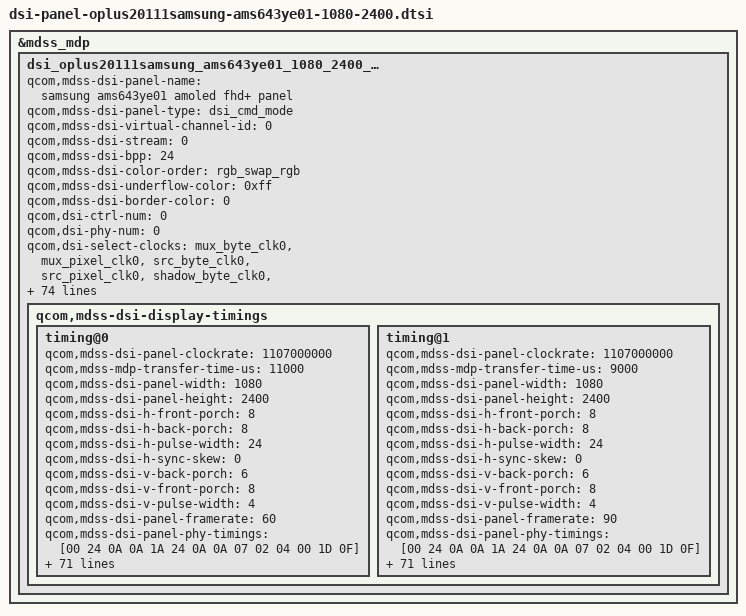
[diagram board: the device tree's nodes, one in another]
// SPDX-License-Identifier: GPL-2.0-only
/*
* Copyright (C) 2018-2020 Oplus. All rights reserved.
*/

&mdss_mdp {
	dsi_oplus20111samsung_ams643ye01_1080_2400_cmd: qcom,mdss_dsi_oplus20111samsung_ams643ye01_1080_2400_cmd {
		qcom,mdss-dsi-panel-name =
		  "samsung ams643ye01 amoled fhd+ panel";
		qcom,mdss-dsi-panel-type = "dsi_cmd_mode";
		qcom,mdss-dsi-virtual-channel-id = <0>;
		qcom,mdss-dsi-stream = <0>;
		qcom,mdss-dsi-bpp = <24>;
		qcom,mdss-dsi-color-order = "rgb_swap_rgb";
		qcom,mdss-dsi-underflow-color = <0xff>;
		qcom,mdss-dsi-border-color = <0>;

		qcom,dsi-ctrl-num = <0>;
		qcom,dsi-phy-num = <0>;
		qcom,dsi-select-clocks = "src_byte_clk0", "src_pixel_clk0";

		qcom,mdss-dsi-traffic-mode = "non_burst_sync_event";
		qcom,mdss-dsi-lane-map = "lane_map_0123";
		qcom,mdss-dsi-bllp-eof-power-mode;
		qcom,mdss-dsi-bllp-power-mode;
		qcom,mdss-dsi-lane-0-state;
		qcom,mdss-dsi-lane-1-state;
		qcom,mdss-dsi-lane-2-state;
		qcom,mdss-dsi-lane-3-state;
		qcom,mdss-dsi-dma-trigger = "trigger_sw";
		qcom,mdss-dsi-mdp-trigger = "none";
		qcom,mdss-dsi-reset-sequence = <1 10>, <0 10>, <1 10>;
		qcom,mdss-dsi-te-pin-select = <1>;
		qcom,mdss-dsi-te-dcs-command = <1>;
		qcom,mdss-dsi-te-check-enable;
		qcom,mdss-dsi-te-using-te-pin;
		qcom,mdss-dsi-wr-mem-start = <0x2c>;
		qcom,mdss-dsi-wr-mem-continue = <0x3c>;
		qcom,mdss-dsi-panel-hdr-enabled;
		qcom,mdss-dsi-panel-hdr-color-primaries = <15000 15500 34000
			16000 13250 34500 7500 3000>;
		qcom,mdss-dsi-panel-peak-brightness = <4300000>;
		qcom,mdss-dsi-panel-blackness-level = <1023>;
		qcom,mdss-pan-physical-width-dimension = <68>;
		qcom,mdss-pan-physical-height-dimension = <152>;
		qcom,esd-check-enabled;
		qcom,mdss-dsi-panel-status-check-mode = "reg_read";
		qcom,mdss-dsi-panel-status-command = [06 01 00 01 05 00 02 0A 00];
		qcom,mdss-dsi-panel-status-command-state = "dsi_hs_mode";
		qcom,mdss-dsi-panel-status-value = <0x9F>;
		qcom,mdss-dsi-panel-status-read-length = <1>;

		qcom,mdss-dsi-display-timings {
			timing@0{
				qcom,mdss-dsi-panel-clockrate = <1107000000>;
				qcom,mdss-mdp-transfer-time-us = <11000>;
				qcom,mdss-dsi-panel-width = <1080>;
				qcom,mdss-dsi-panel-height = <2400>;
				qcom,mdss-dsi-h-front-porch = <8>;
				qcom,mdss-dsi-h-back-porch = <8>;
				qcom,mdss-dsi-h-pulse-width = <24>;
				qcom,mdss-dsi-h-sync-skew = <0>;
				qcom,mdss-dsi-v-back-porch = <6>;
				qcom,mdss-dsi-v-front-porch = <8>;
				qcom,mdss-dsi-v-pulse-width = <4>;
				qcom,mdss-dsi-panel-framerate = <60>;
				qcom,mdss-dsi-panel-phy-timings = [00 24 0A 0A 1A 24 0A 0A 07 02 04 00 1D 0F];
				qcom,display-topology = <2 2 1>;
				qcom,default-topology-index = <0>;
				oplus,fod-on-vblank = <0>;
				oplus,fod-off-vblank = <1>;

				qcom,mdss-dsi-on-command = [
					/*Power Ctrl for T0 panel*/
					39 01 00 00 00 00 03 F0 5A 5A
					39 01 00 00 00 00 03 B0 09 B5
					39 01 00 00 00 00 03 B5 00 00
					39 01 00 00 00 00 03 B0 07 B5
					39 01 00 00 00 00 02 B5 28
					39 01 00 00 20 00 03 F0 A5 A5
					/*PPS Setting*/
					39 01 00 00 00 00 81 9E
					11 00 00 89 30 80 09 60
					04 38 00 1E 02 1C 02 1C
					02 00 02 0E 00 20 02 E3
					00 07 00 0C 03 50 03 64
					18 00 10 F0 03 0C 20 00
					06 0B 0B 33 0E 1C 2A 38
					46 54 62 69 70 77 79 7B
					7D 7E 01 02 01 00 09 40
					09 BE 19 FC 19 FA 19 F8
					1A 38 1A 78 1A B6 2A F6
					2B 34 2B 74 3B 74 6B F4
					00 00 00 00 00 00 00 00
					00 00 00 00 00 00 00 00
					00 00 00 00 00 00 00 00
					00 00 00 00 00 00 00 00
					00 00 00 00 00 00 00 00
					15 01 00 00 00 00 02 C2 14
					15 01 00 00 00 00 02 9D 01
					/*OSC 167M*/
					39 01 00 00 00 00 03 F0 5A 5A
					39 01 00 00 00 00 03 FC 5A 5A
					39 01 00 00 00 00 03 B0 66 C5
					39 01 00 00 00 00 03 C5 00 8C
					39 01 00 00 00 00 03 B0 2A C5
					39 01 00 00 00 00 05 C5 0D 10 80 45
					39 01 00 00 00 00 03 B0 3E C5
					39 01 00 00 00 00 03 C5 4D 3D
					39 01 00 00 00 00 03 F0 A5 A5
					39 01 00 00 00 00 03 FC A5 A5
					05 01 00 00 80 00 01 11
					/* CASET/PASET Setting */
					39 01 00 00 00 00 05 2A 00 00 04 37
					39 01 00 00 00 00 05 2B 00 00 09 5F
					/* FQ CON Setting*/
					39 01 00 00 00 00 03 F0 5A 5A
					39 01 00 00 00 00 03 B0 27 F2
					39 01 00 00 00 00 02 F2 00
					39 01 00 00 00 00 03 F0 A5 A5
					/* TE vsync ON */
					15 01 00 00 00 00 02 35 00
					/*Frequency Change*/
					39 01 00 00 00 00 03 F0 5A 5A
					39 01 00 00 00 00 03 60 00 00
					39 01 00 00 00 00 02 F7 0F
					39 01 00 00 00 00 03 F0 A5 A5
					15 01 00 00 00 00 02 53 20
				];
				qcom,mdss-dsi-post-on-backlight = [
					39 01 00 00 00 00 03 F0 5A 5A
					39 01 00 00 12 00 03 F0 A5 A5
					/* Display On*/
					05 01 00 00 00 00 01 29
				];
				qcom,mdss-dsi-timing-switch-command = [
					/* 60hz Transition */
					39 01 00 00 00 00 03 F0 5A 5A
					39 01 00 00 00 00 03 60 00 00
					39 01 00 00 00 00 02 F7 0F
					39 01 00 00 00 00 03 F0 A5 A5
				];
				qcom,mdss-dsi-off-command = [
					05 01 00 00 0A 00 01 28
					05 01 00 00 96 00 01 10
				];
				qcom,mdss-dsi-lp1-command = [
					05 01 00 00 25 00 01 28
					39 01 00 00 00 00 03 F0 5A 5A
					15 01 00 00 00 00 02 53 25
					15 01 00 00 00 00 02 BB 1D
					39 01 00 00 00 00 03 F0 A5 A5
				];
				qcom,mdss-dsi-nolp-command = [
					15 01 00 00 00 00 02 53 20
					39 01 00 00 00 00 03 9F 5A 5A
					05 01 00 00 00 00 01 29
					39 01 00 00 00 00 03 9F A5 A5
				];
				qcom,mdss-dsi-aod-high-mode-command = [
					15 01 00 00 00 00 02 53 24
				];
				qcom,mdss-dsi-aod-low-mode-command = [
					15 01 00 00 00 00 02 53 25
				];
				qcom,mdss-dsi-aod-hbm-on-command = [
					15 01 00 00 00 00 02 53 E0
					39 01 00 00 00 00 03 51 0F FF
				];
				qcom,mdss-dsi-hbm-on-command = [
					15 01 00 00 00 00 02 53 E0
					39 01 00 00 22 00 03 51 0F FF
				];
				qcom,mdss-dsi-normal-hbm-on-command = [
					15 01 00 00 00 00 02 53 E0
					39 01 00 00 00 00 03 51 0F FF
				];
				qcom,mdss-dsi-hbm-off-command = [
					15 01 00 00 00 00 02 53 20
				];
				qcom,mdss-dsi-aod-hbm-off-command = [
					15 01 00 00 00 00 02 53 25
					39 01 00 00 00 00 03 51 00 01
				];
				qcom,mdss-dsi-seed-off-command = [
					/* CRC OFF */
					39 01 00 00 00 00 03 F0 5A 5A
					15 01 00 00 00 00 02 5D 00
					39 01 00 00 00 00 02 62 01
					39 01 00 00 00 00 03 F0 A5 A5
				];
				qcom,mdss-dsi-seed-0-command = [
					/* SEED CRC Setting */
					39 01 00 00 14 00 03 F0 5A 5A
					39 01 00 00 00 00 04 72 2C 21 00
					39 01 00 00 00 00 02 5D 86
					39 01 00 00 00 00 02 F8 00
					/* SEED CRC ON */
					39 01 00 00 00 00 02 62 00
					/* SEED CRC DCI-P3 */
					39 01 00 00 00 00 03 B0 2B 62
					39 01 00 00 00 00 16 62 D8 00 04 00 FF 02 00 00 FF 18 FF E4 FB 00 F0 F6 EA 01 FF FF FF
					39 01 00 00 11 00 04 72 2C 01 00
					39 01 00 00 00 00 03 F0 A5 A5
				];
				qcom,mdss-dsi-seed-1-command = [
					/* SEED CRC Setting */
					39 01 00 00 14 00 03 F0 5A 5A
					39 01 00 00 00 00 04 72 2C 21 00
					39 01 00 00 00 00 02 5D 06
					39 01 00 00 00 00 02 F8 00
					/* SEED CRC ON */
					39 01 00 00 00 00 02 62 00
					/* SEED CRC sRGB */
					39 01 00 00 00 00 03 B0 01 62
					39 01 00 00 00 00 16 62 B8 00 06 3A D7 17 07 05 D2 48 F2 DC C4 07 C8 E9 E5 1C FF FF FF
					39 01 00 00 11 00 04 72 2C 01 00
					39 01 00 00 00 00 03 F0 A5 A5
				];
				qcom,mdss-dsi-seed-2-command = [
					/* SEED CRC Setting */
					39 01 00 00 14 00 03 F0 5A 5A
					39 01 00 00 00 00 02 5D 46
					39 01 00 00 00 00 04 72 2C 21 00
					39 01 00 00 00 00 02 F8 00
					/* SEED CRC ON */
					39 01 00 00 00 00 02 62 00
					/* SEED CRC Adobe */
					39 01 00 00 00 00 03 B0 16 62
					39 01 00 00 00 00 16 62 D8 00 04 00 FF 02 00 00 FF 18 FF E4 FB 00 F0 F6 EA 01 FF FF FF
					39 01 00 00 11 00 04 72 2C 01 00
					39 01 00 00 00 00 03 F0 A5 A5
				];
				qcom,mdss-dsi-osc-clk-mode0-command = [
					/*OSC 167M*/
					39 01 00 00 00 00 03 F0 5A 5A
					39 01 00 00 00 00 03 FC 5A 5A
					39 01 00 00 00 00 03 B0 66 C5
					39 01 00 00 00 00 03 C5 00 8C
					39 01 00 00 00 00 03 B0 2A C5
					39 01 00 00 00 00 05 C5 0D 10 80 45
					39 01 00 00 00 00 03 B0 3E C5
					39 01 00 00 00 00 03 C5 4D 3D
					39 01 00 00 00 00 03 F0 A5 A5
					39 01 00 00 00 00 03 FC A5 A5
				];
				qcom,mdss-dsi-osc-clk-mode1-command = [
					/*OSC 169M*/
					39 01 00 00 00 00 03 F0 5A 5A
					39 01 00 00 00 00 03 FC 5A 5A
					39 01 00 00 00 00 03 B0 66 C5
					39 01 00 00 00 00 03 C5 00 8C
					39 01 00 00 00 00 03 B0 2A C5
					39 01 00 00 00 00 05 C5 0D 10 80 45
					39 01 00 00 00 00 03 B0 3E C5
					39 01 00 00 00 00 03 C5 4E 2A
					39 01 00 00 00 00 03 F0 A5 A5
					39 01 00 00 00 00 03 FC A5 A5
				];
				qcom,mdss-dsi-hbm-enter-switch-command = [
					39 01 00 00 00 00 02 53 E0
				];
				qcom,mdss-dsi-hbm-exit-switch-command = [
					39 01 00 00 00 00 02 53 20
				];
				qcom,mdss-dsi-aod-hbm-on-command-state = "dsi_hs_mode";
				qcom,mdss-dsi-aod-hbm-off-command-state = "dsi_hs_mode";
				qcom,mdss-dsi-seed-off-command-state = "dsi_hs_mode";
				qcom,mdss-dsi-seed-0-command-state = "dsi_hs_mode";
				qcom,mdss-dsi-seed-1-command-state = "dsi_hs_mode";
				qcom,mdss-dsi-seed-2-command-state = "dsi_hs_mode";
				qcom,mdss-dsi-lp1-command-state = "dsi_hs_mode";
				qcom,mdss-dsi-nolp-command-state = "dsi_hs_mode";
				qcom,mdss-dsi-post-on-backlight-state = "dsi_hs_mode";
				qcom,mdss-dsi-on-command-state = "dsi_hs_mode";
				qcom,mdss-dsi-off-command-state = "dsi_hs_mode";
				qcom,compression-mode = "dsc";
				qcom,mdss-dsc-slice-height = <30>;
				qcom,mdss-dsc-slice-width = <540>;
				qcom,mdss-dsc-slice-per-pkt = <2>;
				qcom,mdss-dsc-bit-per-component = <8>;
				qcom,mdss-dsc-bit-per-pixel = <8>;
				qcom,mdss-dsc-block-prediction-enable;
			};

			timing@1{
				qcom,mdss-dsi-panel-clockrate = <1107000000>;
				qcom,mdss-mdp-transfer-time-us = <9000>;
				qcom,mdss-dsi-panel-width = <1080>;
				qcom,mdss-dsi-panel-height = <2400>;
				qcom,mdss-dsi-h-front-porch = <8>;
				qcom,mdss-dsi-h-back-porch = <8>;
				qcom,mdss-dsi-h-pulse-width = <24>;
				qcom,mdss-dsi-h-sync-skew = <0>;
				qcom,mdss-dsi-v-back-porch = <6>;
				qcom,mdss-dsi-v-front-porch = <8>;
				qcom,mdss-dsi-v-pulse-width = <4>;
				qcom,mdss-dsi-panel-framerate = <90>;
				qcom,mdss-dsi-panel-phy-timings = [00 24 0A 0A 1A 24 0A 0A 07 02 04 00 1D 0F];
				qcom,display-topology = <2 2 1>;
				qcom,default-topology-index = <0>;
				oplus,fod-on-vblank = <1>;
				oplus,fod-off-vblank = <1>;
				qcom,mdss-dsi-on-command = [
					/*Power Ctrl for T0 panel*/
					39 01 00 00 00 00 03 F0 5A 5A
					39 01 00 00 00 00 03 B0 09 B5
					39 01 00 00 00 00 03 B5 00 00
					39 01 00 00 00 00 03 B0 07 B5
					39 01 00 00 00 00 02 B5 28
					39 01 00 00 20 00 03 F0 A5 A5
					/*PPS Setting*/
					39 01 00 00 00 00 81 9E
					11 00 00 89 30 80 09 60
					04 38 00 1E 02 1C 02 1C
					02 00 02 0E 00 20 02 E3
					00 07 00 0C 03 50 03 64
					18 00 10 F0 03 0C 20 00
					06 0B 0B 33 0E 1C 2A 38
					46 54 62 69 70 77 79 7B
					7D 7E 01 02 01 00 09 40
					09 BE 19 FC 19 FA 19 F8
					1A 38 1A 78 1A B6 2A F6
					2B 34 2B 74 3B 74 6B F4
					00 00 00 00 00 00 00 00
					00 00 00 00 00 00 00 00
					00 00 00 00 00 00 00 00
					00 00 00 00 00 00 00 00
					00 00 00 00 00 00 00 00
					15 01 00 00 00 00 02 C2 14
					15 01 00 00 00 00 02 9D 01
					/*OSC 167M*/
					39 01 00 00 00 00 03 F0 5A 5A
					39 01 00 00 00 00 03 FC 5A 5A
					39 01 00 00 00 00 03 B0 66 C5
					39 01 00 00 00 00 03 C5 00 8C
					39 01 00 00 00 00 03 B0 2A C5
					39 01 00 00 00 00 05 C5 0D 10 80 45
					39 01 00 00 00 00 03 B0 3E C5
					39 01 00 00 00 00 03 C5 4D 3D
					39 01 00 00 00 00 03 F0 A5 A5
					39 01 00 00 00 00 03 FC A5 A5
					05 01 00 00 80 00 01 11
					/* CASET/PASET Setting */
					39 01 00 00 00 00 05 2A 00 00 04 37
					39 01 00 00 00 00 05 2B 00 00 09 5F
					/* FQ CON Setting*/
					39 01 00 00 00 00 03 F0 5A 5A
					39 01 00 00 00 00 03 B0 27 F2
					39 01 00 00 00 00 02 F2 00
					39 01 00 00 00 00 03 F0 A5 A5
					/* TE vsync ON */
					15 01 00 00 00 00 02 35 00
					/*Frequency Change*/
					39 01 00 00 00 00 03 F0 5A 5A
					39 01 00 00 00 00 03 60 08 00
					39 01 00 00 00 00 02 F7 0F
					39 01 00 00 00 00 03 F0 A5 A5
					15 01 00 00 00 00 02 53 20
				];
				qcom,mdss-dsi-post-on-backlight = [
					/* Display On*/
					05 01 00 00 00 00 01 29
				];
				qcom,mdss-dsi-timing-switch-command = [
					/* 90hz Transition */
					39 01 00 00 00 00 03 F0 5A 5A
					39 01 00 00 00 00 03 60 08 00
					39 01 00 00 00 00 02 F7 0F
					39 01 00 00 00 00 03 F0 A5 A5
				];
				qcom,mdss-dsi-off-command = [
					05 01 00 00 0A 00 01 28
					05 01 00 00 96 00 01 10
				];
				qcom,mdss-dsi-lp1-command = [
					/* AOD on */
					05 01 00 00 25 00 01 28
					39 01 00 00 00 00 03 F0 5A 5A
					15 01 00 00 00 00 02 53 25
					15 01 00 00 00 00 02 BB 1D
					39 01 00 00 00 00 03 F0 A5 A5
					05 01 00 00 00 00 01 29
				];
				qcom,mdss-dsi-nolp-command = [
					39 01 00 00 00 00 03 F0 5A 5A
					15 01 00 00 00 00 02 53 20
					39 01 00 00 00 00 03 F0 A5 A5
					05 01 00 00 00 00 01 29
				];
				qcom,mdss-dsi-aod-high-mode-command = [
					15 01 00 00 00 00 02 53 24
				];
				qcom,mdss-dsi-aod-low-mode-command = [
					15 01 00 00 00 00 02 53 25
				];
				qcom,mdss-dsi-aod-hbm-on-command = [
					15 01 00 00 00 00 02 53 E0
					39 01 00 00 00 00 03 51 0F FF
					];
				qcom,mdss-dsi-hbm-on-command = [
					15 01 00 00 00 00 02 53 E0
					39 01 00 00 22 00 03 51 0F FF
				];
				qcom,mdss-dsi-normal-hbm-on-command = [
					15 01 00 00 00 00 02 53 E0
					39 01 00 00 00 00 03 51 0F FF
				];
				qcom,mdss-dsi-hbm-off-command = [
					15 01 00 00 00 00 02 53 20
				];
				qcom,mdss-dsi-aod-hbm-off-command = [
					15 01 00 00 00 00 02 53 25
					39 01 00 00 00 00 03 51 00 01
				];
				qcom,mdss-dsi-seed-off-command = [
					/* CRC OFF */
					39 01 00 00 00 00 03 F0 5A 5A
					15 01 00 00 00 00 02 5D 00
					39 01 00 00 00 00 02 62 01
					39 01 00 00 00 00 03 F0 A5 A5
				];
				qcom,mdss-dsi-seed-0-command = [
					/* SEED CRC Setting */
					39 01 00 00 14 00 03 F0 5A 5A
					39 01 00 00 00 00 04 72 2C 21 00
					39 01 00 00 00 00 02 5D 86
					39 01 00 00 00 00 02 F8 00
					/* SEED CRC ON */
					39 01 00 00 00 00 02 62 00
					/* SEED CRC DCI-P3 */
					39 01 00 00 00 00 03 B0 2B 62
					39 01 00 00 00 00 16 62 D8 00 04 00 FF 02 00 00 FF 18 FF E4 FB 00 F0 F6 EA 01 FF FF FF
					39 01 00 00 0C 00 04 72 2C 01 00
					39 01 00 00 00 00 03 F0 A5 A5
				];
				qcom,mdss-dsi-seed-1-command = [
					/* SEED CRC Setting */
					39 01 00 00 14 00 03 F0 5A 5A
					39 01 00 00 00 00 04 72 2C 21 00
					39 01 00 00 00 00 02 5D 06
					39 01 00 00 00 00 02 F8 00
					/* SEED CRC ON */
					39 01 00 00 00 00 02 62 00
					/* SEED CRC sRGB */
					39 01 00 00 00 00 03 B0 01 62
					39 01 00 00 00 00 16 62 B8 00 06 3A D7 17 07 05 D2 48 F2 DC C4 07 C8 E9 E5 1C FF FF FF
					39 01 00 00 0C 00 04 72 2C 01 00
					39 01 00 00 00 00 03 F0 A5 A5
				];
				qcom,mdss-dsi-seed-2-command = [
					/* SEED CRC Setting */
					39 01 00 00 14 00 03 F0 5A 5A
					39 01 00 00 00 00 02 5D 46
					39 01 00 00 00 00 04 72 2C 21 00
					39 01 00 00 00 00 02 F8 00
					/* SEED CRC ON */
					39 01 00 00 00 00 02 62 00
					/* SEED CRC Adobe */
					39 01 00 00 00 00 03 B0 16 62
					39 01 00 00 00 00 16 62 D8 00 04 00 FF 02 00 00 FF 18 FF E4 FB 00 F0 F6 EA 01 FF FF FF
					39 01 00 00 0C 00 04 72 2C 01 00
					39 01 00 00 00 00 03 F0 A5 A5
				];
				qcom,mdss-dsi-osc-clk-mode0-command = [
					/*OSC 167M*/
					39 01 00 00 00 00 03 F0 5A 5A
					39 01 00 00 00 00 03 FC 5A 5A
					39 01 00 00 00 00 03 B0 66 C5
					39 01 00 00 00 00 03 C5 00 8C
					39 01 00 00 00 00 03 B0 2A C5
					39 01 00 00 00 00 05 C5 0D 10 80 45
					39 01 00 00 00 00 03 B0 3E C5
					39 01 00 00 00 00 03 C5 4D 3D
					39 01 00 00 00 00 03 F0 A5 A5
					39 01 00 00 00 00 03 FC A5 A5
				];
				qcom,mdss-dsi-osc-clk-mode1-command = [
					/*OSC 169M*/
					39 01 00 00 00 00 03 F0 5A 5A
					39 01 00 00 00 00 03 FC 5A 5A
					39 01 00 00 00 00 03 B0 66 C5
					39 01 00 00 00 00 03 C5 00 8C
					39 01 00 00 00 00 03 B0 2A C5
					39 01 00 00 00 00 05 C5 0D 10 80 45
					39 01 00 00 00 00 03 B0 3E C5
					39 01 00 00 00 00 03 C5 4E 2A
					39 01 00 00 00 00 03 F0 A5 A5
					39 01 00 00 00 00 03 FC A5 A5
				];
				qcom,mdss-dsi-hbm-enter-switch-command = [
					39 01 00 00 00 00 02 53 E0
				];
				qcom,mdss-dsi-hbm-exit-switch-command = [
					39 01 00 00 00 00 02 53 20
				];

				qcom,mdss-dsi-aod-hbm-on-command-state = "dsi_hs_mode";
				qcom,mdss-dsi-aod-hbm-off-command-state = "dsi_hs_mode";
				qcom,mdss-dsi-seed-off-command-state = "dsi_hs_mode";
				qcom,mdss-dsi-seed-0-command-state = "dsi_hs_mode";
				qcom,mdss-dsi-seed-1-command-state = "dsi_hs_mode";
				qcom,mdss-dsi-seed-2-command-state = "dsi_hs_mode";
				qcom,mdss-dsi-lp1-command-state = "dsi_hs_mode";
				qcom,mdss-dsi-nolp-command-state = "dsi_hs_mode";
				qcom,mdss-dsi-post-on-backlight-state = "dsi_hs_mode";
				qcom,mdss-dsi-on-command-state = "dsi_hs_mode";
				qcom,mdss-dsi-off-command-state = "dsi_hs_mode";
				qcom,compression-mode = "dsc";
				qcom,mdss-dsc-slice-height = <30>;
				qcom,mdss-dsc-slice-width = <540>;
				qcom,mdss-dsc-slice-per-pkt = <2>;
				qcom,mdss-dsc-bit-per-component = <8>;
				qcom,mdss-dsc-bit-per-pixel = <8>;
				qcom,mdss-dsc-block-prediction-enable;
			};
		};
	};
};

&dsi_oplus20111samsung_ams643ye01_1080_2400_cmd {
	qcom,panel-supply-entries = <&dsi_panel_pwr_supply_vout>;
	qcom,mdss-dsi-bl-pmic-control-type = "bl_ctrl_dcs";
	qcom,mdss-dsi-bl-min-level = <1>;
	qcom,mdss-dsi-bl-max-level = <4095>;
	qcom,mdss-brightness-max-level = <4095>;
	qcom,mdss-dsi-bl-normal-max-level = <2047>;
	qcom,mdss-brightness-normal-max-level = <2047>;
	qcom,mdss-brightness-default-level = <400>;
	qcom,platform-te-gpio = <&tlmm 10 0>;
	qcom,platform-reset-gpio = <&pm8150l_gpios 3 0>;
	oplus,mdss-dsi-vendor-name = "AMS643YE01";
	oplus,mdss-dsi-manufacture = "samsung1024";
	qcom,mdss-dsi-dc-backlight-level = <520>;
	oplus,osc-support;
	oplus,mdss-dsi-osc-clk-mode0-rate = <167000>;
	oplus,mdss-dsi-osc-clk-mode1-rate = <169000>;

	oplus,dsi-fod-brightness = <0 0xff>,
				<2 0xef>,
				<4 0xEA>,
				<6 0xE9>,
				<8 0xE5>,
				<10 0xE3>,
				<20 0xE0>,
				<40 0xD8>,
				<60 0xD0>,
				<90 0xCD>,
				<140 0xC5>,
				<200 0xB9>,
				<300 0xAE>,
				<450 0x9F>,
				<600 0x93>,
				<800 0x7A>,
				<1000 0x67>,
				<1200 0x52>,
				<1400 0x49>,
				<1600 0x3C>,
				<1800 0x2F>,
				<2047 0x1E>;

	oplus,dsi-dc-brightness = <0 0xFF>,
				<1 0xFE>,
				<2 0xFC>,
				<3 0xFB>,
				<4 0xF9>,
				<5 0xF9>,
				<8 0xF6>,
				<10 0xF5>,
				<15 0xF3>,
				<20 0xF2>,
				<30 0xEF>,
				<40 0xEA>,
				<60 0xE0>,
				<80 0xD3>,
				<110 0xC4>,
				<140 0xB4>,
				<170 0xA6>,
				<210 0x98>,
				<250 0x83>,
				<300 0x66>,
				<350 0x4A>,
				<400 0x32>,
				<460 0x12>,
				<520 0x00>;

	qcom,ulps-enabled;
	qcom,dsi-select-clocks = "mux_byte_clk0", "mux_pixel_clk0",
				"src_byte_clk0", "src_pixel_clk0",
				"shadow_byte_clk0", "shadow_pixel_clk0";
	qcom,mdss-dsi-t-clk-post = <0x0F>;
	qcom,mdss-dsi-t-clk-pre = <0x1D>;
	qcom,mdss-dsi-display-timings {
		timing@0{
			qcom,mdss-dsi-panel-phy-timings = [00 24 0A 0A 1A 24 0A 0A 07 02 04 00 1D 0F];

			qcom,display-topology = <2 2 1>;
			qcom,default-topology-index = <0>;
		};
		timing@1{
			qcom,mdss-dsi-panel-phy-timings = [00 24 0A 0A 1A 24 0A 0A 07 02 04 00 1D 0F];

			qcom,display-topology = <2 2 1>;
			qcom,default-topology-index = <0>;
		};
	};
};

&dsi_oplus20111samsung_ams643ye01_1080_2400_cmd {
	qcom,panel_voltage_vddi_name = "vddio";
	qcom,panel_voltage_vddi = <0 1800000 1800000 1800000>;
	qcom,panel_voltage_vddr_name = "vout";
	qcom,panel_voltage_vddr = <1 1500000 1500000 1500000>;
};
